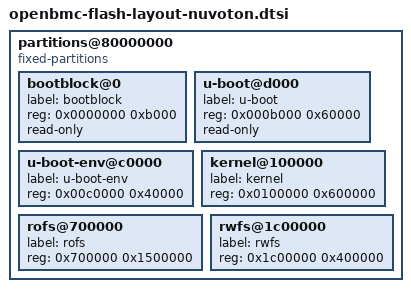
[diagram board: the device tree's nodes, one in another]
partitions@80000000 {
	compatible = "fixed-partitions";
	#address-cells = <1>;
	#size-cells = <1>;
	bootblock@0 {
		label = "bootblock";
		reg = <0x0000000 0xb000>;
		read-only;
	};
	u-boot@d000 {
		label = "u-boot";
		reg = <0x000b000 0x60000>;
		read-only;
	};
	u-boot-env@c0000{
		label = "u-boot-env";
		reg = <0x00c0000 0x40000>;
	};
	kernel@100000 {
		label = "kernel";
		reg = <0x0100000 0x600000>;
	};
	rofs@700000 {
		label = "rofs";
		reg = <0x700000 0x1500000>;
	};
	rwfs@1c00000 {
		label = "rwfs";
		reg = <0x1c00000 0x400000>;
	};
};
